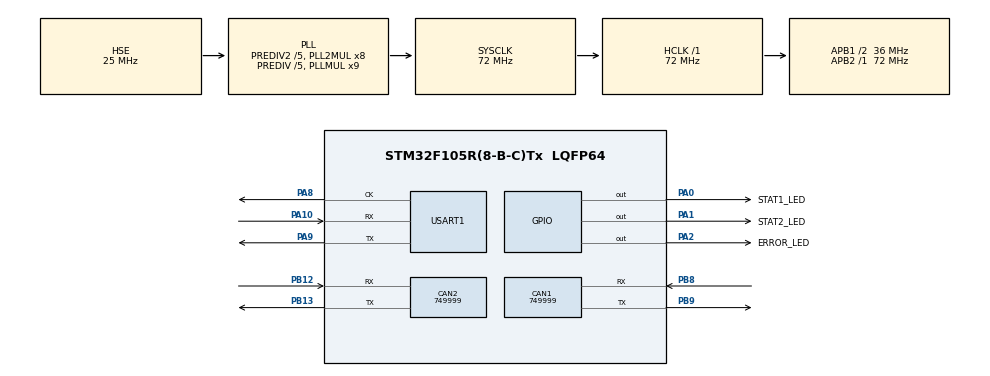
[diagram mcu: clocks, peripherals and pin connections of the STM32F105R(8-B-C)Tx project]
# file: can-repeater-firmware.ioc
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CAN1.ABOM=ENABLE
CAN1.BS1=CAN_BS1_1TQ
CAN1.BS2=CAN_BS2_1TQ
CAN1.CalculateBaudRate=749999
CAN1.CalculateTimeBit=1333
CAN1.CalculateTimeQuantum=444.44444444444446
CAN2.ABOM=ENABLE
CAN2.BS1=CAN_BS1_1TQ
CAN2.BS2=CAN_BS2_1TQ
CAN2.CalculateBaudRate=749999
CAN2.CalculateTimeBit=1333
CAN2.CalculateTimeQuantum=444.44444444444446
Mcu.Family=STM32F1
Mcu.Name=STM32F105R(8-B-C)Tx
Mcu.Package=LQFP64
NVIC.CAN1_RX0_IRQn=true\:0\:0\:false\:false\:true\:true\:true\:true
NVIC.CAN1_SCE_IRQn=true\:0\:0\:false\:false\:true\:true\:true\:true
NVIC.CAN2_RX0_IRQn=true\:0\:0\:false\:false\:true\:true\:true\:true
NVIC.CAN2_SCE_IRQn=true\:0\:0\:false\:false\:true\:true\:true\:true
NVIC.PriorityGroup=NVIC_PRIORITYGROUP_4
PA0-WKUP.GPIO_Label=STAT1_LED
PA0-WKUP.Signal=GPIO_Output
PA1.GPIO_Label=STAT2_LED
PA1.Signal=GPIO_Output
PA10.Mode=Synchronous
PA10.Signal=USART1_RX
PA13.Mode=JTAG_4_pins
PA13.Signal=SYS_JTMS-SWDIO
PA14.Mode=JTAG_4_pins
PA14.Signal=SYS_JTCK-SWCLK
PA15.Mode=JTAG_4_pins
PA15.Signal=SYS_JTDI
PA2.GPIO_Label=ERROR_LED
PA2.Signal=GPIO_Output
PA8.Mode=Synchronous
PA8.Signal=USART1_CK
PA9.Mode=Synchronous
PA9.Signal=USART1_TX
PB12.Mode=CAN_Activate
PB12.Signal=CAN2_RX
PB13.Mode=CAN_Activate
PB13.Signal=CAN2_TX
PB3.Mode=JTAG_4_pins
PB3.Signal=SYS_JTDO
PB8.Mode=CAN_Activate
PB8.Signal=CAN1_RX
PB9.Mode=CAN_Activate
PB9.Signal=CAN1_TX
PD0-OSC_IN.Mode=HSE-External-Oscillator
PD0-OSC_IN.Signal=RCC_OSC_IN
PD1-OSC_OUT.Mode=HSE-External-Oscillator
PD1-OSC_OUT.Signal=RCC_OSC_OUT
ProjectManager.HeapSize=0x200
ProjectManager.StackSize=0x400
ProjectManager.TargetToolchain=Makefile
RCC.AHBFreq_Value=72000000
RCC.APB1CLKDivider=RCC_HCLK_DIV2
RCC.APB1Freq_Value=36000000
RCC.APB1TimFreq_Value=72000000
RCC.APB2Freq_Value=72000000
RCC.APB2TimFreq_Value=72000000
RCC.HCLKFreq_Value=72000000
RCC.HSEDivPLL=RCC_HSE_PREDIV_DIV5
RCC.HSE_VALUE=25000000
RCC.PLLMUL=RCC_PLL_MUL9
RCC.PLLSourceVirtual=RCC_PLLSOURCE_HSE
RCC.Prediv1Source=RCC_PREDIV1_SOURCE_PLL2
RCC.Prediv2=RCC_HSE_PREDIV2_DIV5
RCC.SYSCLKFreq_VALUE=72000000
RCC.SYSCLKSource=RCC_SYSCLKSOURCE_PLLCLK
RCC.USBFreq_Value=48000000
USART1.VirtualMode=VM_SYNC
board=custom

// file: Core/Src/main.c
/* USER CODE BEGIN Header */
/**
  ******************************************************************************
  * @file           : main.c
  * @brief          : Main program body
  ******************************************************************************
  * @attention
  *
  * Copyright (c) 2025 STMicroelectronics.
  * All rights reserved.
  *
  * This software is licensed under terms that can be found in the LICENSE file
  * in the root directory of this software component.
  * If no LICENSE file comes with this software, it is provided AS-IS.
  *
  ******************************************************************************
  */
/* USER CODE END Header */
#include "main.h"
#include "can.h"
#include "usart.h"
#include "gpio.h"

/* USER CODE BEGIN Includes */
#include "can_repeater.h"
/* USER CODE END Includes */

void SystemClock_Config(void);

int main(void)
{

  /* MCU Configuration--------------------------------------------------------*/

  /* Reset of all peripherals, Initializes the Flash interface and the Systick. */
  HAL_Init();

  /* Configure the system clock */
  SystemClock_Config();

  /* Initialize all configured peripherals */
  MX_GPIO_Init();
  MX_CAN1_Init();
  MX_CAN2_Init();
  MX_USART1_Init();
  /* USER CODE BEGIN 2 */
  Repeater_Init();
  /* USER CODE END 2 */

  /* Infinite loop */
  while (1)
  {

    /* USER CODE BEGIN 3 */
    Repeater_Process();
  }
  /* USER CODE END 3 */
}

void SystemClock_Config(void)
{
  RCC_OscInitTypeDef RCC_OscInitStruct = {0};
  RCC_ClkInitTypeDef RCC_ClkInitStruct = {0};

  /** Initializes the RCC Oscillators according to the specified parameters
  * in the RCC_OscInitTypeDef structure.
  */
  RCC_OscInitStruct.OscillatorType = RCC_OSCILLATORTYPE_HSE;
  RCC_OscInitStruct.HSEState = RCC_HSE_ON;
  RCC_OscInitStruct.HSEPredivValue = RCC_HSE_PREDIV_DIV5;
  RCC_OscInitStruct.HSIState = RCC_HSI_ON;
  RCC_OscInitStruct.Prediv1Source = RCC_PREDIV1_SOURCE_PLL2;
  RCC_OscInitStruct.PLL.PLLState = RCC_PLL_ON;
  RCC_OscInitStruct.PLL.PLLSource = RCC_PLLSOURCE_HSE;
  RCC_OscInitStruct.PLL.PLLMUL = RCC_PLL_MUL9;
  RCC_OscInitStruct.PLL2.PLL2State = RCC_PLL2_ON;
  RCC_OscInitStruct.PLL2.PLL2MUL = RCC_PLL2_MUL8;
  RCC_OscInitStruct.PLL2.HSEPrediv2Value = RCC_HSE_PREDIV2_DIV5;
  if (HAL_RCC_OscConfig(&RCC_OscInitStruct) != HAL_OK)
  {
    Error_Handler();
  }

  /** Initializes the CPU, AHB and APB buses clocks
  */
  RCC_ClkInitStruct.ClockType = RCC_CLOCKTYPE_HCLK|RCC_CLOCKTYPE_SYSCLK
                              |RCC_CLOCKTYPE_PCLK1|RCC_CLOCKTYPE_PCLK2;
  RCC_ClkInitStruct.SYSCLKSource = RCC_SYSCLKSOURCE_PLLCLK;
  RCC_ClkInitStruct.AHBCLKDivider = RCC_SYSCLK_DIV1;
  RCC_ClkInitStruct.APB1CLKDivider = RCC_HCLK_DIV2;
  RCC_ClkInitStruct.APB2CLKDivider = RCC_HCLK_DIV1;

  if (HAL_RCC_ClockConfig(&RCC_ClkInitStruct, FLASH_LATENCY_2) != HAL_OK)
  {
    Error_Handler();
  }

  /** Configure the Systick interrupt time
  */
  __HAL_RCC_PLLI2S_ENABLE();
}

void Error_Handler(void)
{
  /* USER CODE BEGIN Error_Handler_Debug */
	HAL_GPIO_WritePin(ERROR_LED_GPIO_Port, ERROR_LED_Pin, GPIO_PIN_SET);
  /* User can add his own implementation to report the HAL error return state */
  __disable_irq();
  while (1)
  {
  }
  /* USER CODE END Error_Handler_Debug */
}
